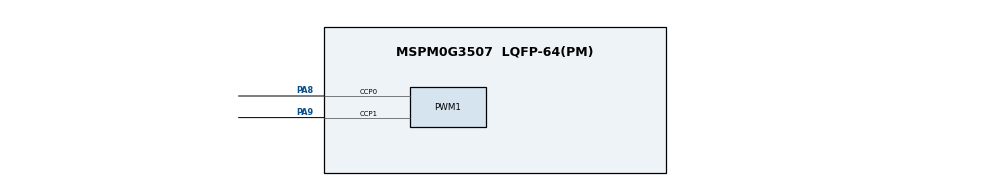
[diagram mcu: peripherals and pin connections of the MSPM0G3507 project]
/**
 * These arguments were used when this file was generated. They will be automatically applied on subsequent loads
 * via the GUI or CLI. Run CLI with '--help' for additional information on how to override these arguments.
 * @cliArgs --device "MSPM0G350X" --part "Default" --package "LQFP-64(PM)" --product "mspm0_sdk@2.11.00.07"
 * @v2CliArgs --device "MSPM0G3507" --package "LQFP-64(PM)" --product "mspm0_sdk@2.11.00.07"
 * @versions {"tool":"1.26.2+4477"}
 */

/**
 * Import the modules used in this configuration.
 */
const GPIO   = scripting.addModule("/ti/driverlib/GPIO", {}, false);
const GPIO1  = GPIO.addInstance();
const GPIO2  = GPIO.addInstance();
const GPIO3  = GPIO.addInstance();
const GPIO4  = GPIO.addInstance();
const PWM    = scripting.addModule("/ti/driverlib/PWM", {}, false);
const PWM1   = PWM.addInstance();
const SYSCTL = scripting.addModule("/ti/driverlib/SYSCTL");
const TIMER  = scripting.addModule("/ti/driverlib/TIMER", {}, false);
const TIMER1 = TIMER.addInstance();

/**
 * Write custom configuration values to the imported modules.
 */
GPIO1.port                          = "PORTB";
GPIO1.$name                         = "GPIO_MOTOR_DIR";
GPIO1.associatedPins.create(4);
GPIO1.associatedPins[0].$name       = "AIN1";
GPIO1.associatedPins[0].assignedPin = "4";
GPIO1.associatedPins[1].$name       = "AIN2";
GPIO1.associatedPins[1].assignedPin = "5";
GPIO1.associatedPins[2].$name       = "BIN1";
GPIO1.associatedPins[2].assignedPin = "12";
GPIO1.associatedPins[3].$name       = "BIN2";
GPIO1.associatedPins[3].assignedPin = "13";

const Board = scripting.addModule("/ti/driverlib/Board", {}, false);

GPIO2.$name                          = "GPIO_MOTOR_STBY";
GPIO2.associatedPins[0].assignedPort = "PORTB";
GPIO2.associatedPins[0].$name        = "STBY";
GPIO2.associatedPins[0].assignedPin  = "3";

GPIO3.$name                         = "GPIO_ENCODER";
GPIO3.port                          = "PORTB";
GPIO3.associatedPins.create(4);
GPIO3.associatedPins[0].$name       = "LEFT_A";
GPIO3.associatedPins[0].direction   = "INPUT";
GPIO3.associatedPins[0].internalResistor = "PULL_UP";
GPIO3.associatedPins[0].interruptEn = true;
GPIO3.associatedPins[0].polarity    = "RISE_FALL";
GPIO3.associatedPins[0].assignedPin = "7";
GPIO3.associatedPins[1].$name       = "LEFT_B";
GPIO3.associatedPins[1].direction   = "INPUT";
GPIO3.associatedPins[1].internalResistor = "PULL_UP";
GPIO3.associatedPins[1].interruptEn = true;
GPIO3.associatedPins[1].polarity    = "RISE_FALL";
GPIO3.associatedPins[1].assignedPin = "6";
GPIO3.associatedPins[2].$name       = "RIGHT_A";
GPIO3.associatedPins[2].direction   = "INPUT";
GPIO3.associatedPins[2].internalResistor = "PULL_UP";
GPIO3.associatedPins[2].interruptEn = true;
GPIO3.associatedPins[2].polarity    = "RISE_FALL";
GPIO3.associatedPins[2].assignedPin = "9";
GPIO3.associatedPins[3].$name       = "RIGHT_B";
GPIO3.associatedPins[3].direction   = "INPUT";
GPIO3.associatedPins[3].internalResistor = "PULL_UP";
GPIO3.associatedPins[3].interruptEn = true;
GPIO3.associatedPins[3].polarity    = "RISE_FALL";
GPIO3.associatedPins[3].assignedPin = "8";

GPIO4.$name                              = "GPIO_GRAY";
GPIO4.port                               = "PORTB";
GPIO4.associatedPins.create(2);
GPIO4.associatedPins[0].$name            = "CLK";
GPIO4.associatedPins[0].assignedPin      = "15";
GPIO4.associatedPins[1].$name            = "DAT";
GPIO4.associatedPins[1].direction        = "INPUT";
GPIO4.associatedPins[1].internalResistor = "PULL_UP";
GPIO4.associatedPins[1].assignedPin      = "14";

PWM1.$name                              = "PWM_MOTOR";
PWM1.timerStartTimer                    = true;
PWM1.peripheral.ccp0Pin.$assign         = "PA8";
PWM1.peripheral.ccp1Pin.$assign         = "PA9";
PWM1.PWM_CHANNEL_0.$name                = "ti_driverlib_pwm_PWMTimerCC0";
PWM1.PWM_CHANNEL_1.$name                = "ti_driverlib_pwm_PWMTimerCC1";
PWM1.ccp0PinConfig.$name                = "ti_driverlib_gpio_GPIOPinGeneric0";
PWM1.ccp0PinConfig.direction            = scripting.forceWrite("OUTPUT");
PWM1.ccp0PinConfig.hideOutputInversion  = scripting.forceWrite(false);
PWM1.ccp0PinConfig.onlyInternalResistor = scripting.forceWrite(false);
PWM1.ccp0PinConfig.passedPeripheralType = scripting.forceWrite("Digital");
PWM1.ccp0PinConfig.enableConfig         = true;
PWM1.ccp1PinConfig.$name                = "ti_driverlib_gpio_GPIOPinGeneric1";
PWM1.ccp1PinConfig.direction            = scripting.forceWrite("OUTPUT");
PWM1.ccp1PinConfig.hideOutputInversion  = scripting.forceWrite(false);
PWM1.ccp1PinConfig.onlyInternalResistor = scripting.forceWrite(false);
PWM1.ccp1PinConfig.passedPeripheralType = scripting.forceWrite("Digital");
PWM1.ccp1PinConfig.enableConfig         = true;

SYSCTL.forceDefaultClkConfig = true;
SYSCTL.clockTreeEn           = true;

TIMER1.$name       = "TIMER_CONTROL";
TIMER1.timerClkDiv = 8;
TIMER1.timerMode   = "PERIODIC";
TIMER1.timerPeriod = "10 ms";
TIMER1.interrupts  = ["ZERO"];

/**
 * Pinmux solution for unlocked pins/peripherals. This ensures that minor changes to the automatic solver in a future
 * version of the tool will not impact the pinmux you originally saw.  These lines can be completely deleted in order to
 * re-solve from scratch.
 */
GPIO1.associatedPins[0].pin.$suggestSolution = "PB4";
GPIO1.associatedPins[1].pin.$suggestSolution = "PB5";
GPIO1.associatedPins[2].pin.$suggestSolution = "PB12";
GPIO1.associatedPins[3].pin.$suggestSolution = "PB13";
Board.peripheral.$suggestSolution            = "DEBUGSS";
Board.peripheral.swclkPin.$suggestSolution   = "PA20";
Board.peripheral.swdioPin.$suggestSolution   = "PA19";
GPIO2.associatedPins[0].pin.$suggestSolution = "PB3";
GPIO3.associatedPins[0].pin.$suggestSolution = "PB7";
GPIO3.associatedPins[1].pin.$suggestSolution = "PB6";
GPIO3.associatedPins[2].pin.$suggestSolution = "PB9";
GPIO3.associatedPins[3].pin.$suggestSolution = "PB8";
GPIO4.associatedPins[0].pin.$suggestSolution = "PB15";
GPIO4.associatedPins[1].pin.$suggestSolution = "PB14";
PWM1.peripheral.$suggestSolution             = "TIMA0";
TIMER1.peripheral.$suggestSolution           = "TIMA1";
